# STM32WBA52xx register map
File version: 1.0
Registers are 32-bit, read-write, reset 0x0 unless marked. A register's access mark holds for its fields unless they carry their own. Offsets are from the block's base; lines under a group give offsets from that group; [hi:lo] are bit positions; {n}, {i} and the like mark numbered series; 'fields as' and 'values as' point back to an identical list; <NAME> marks a mode.

## Memory map
0x0BF8FE40 RSSLIB_PFUNC — RSSLib function pointer structure
0x40000000 TIM2 — TIM
0x40000400 TIM3 — TIM
0x40002C00 WWDG
0x40003000 IWDG
0x40004400 USART2 — Universal Synchronous Asynchronous Receiver Transmitter
0x40005400 I2C1 — Inter-integrated Circuit Interface
0x40009400 LPTIM2 — LPTIMER
0x40012C00 TIM1 — TIM
0x40013000 SPI1 — SPI
0x40013800 USART1 — Universal Synchronous Asynchronous Receiver Transmitter
0x40014400 TIM16 — TIM
0x40014800 TIM17 — TIM
0x40020000 GPDMA1 — DMA Controller
0x40022000 FLASH — FLASH Registers
0x40023000 CRC — CRC calculation unit
0x40024000 TSC
0x40026000 RAMCFG
0x40030400 ICACHE — Instruction Cache
0x40032400 GTZC_TZSC — Global TrustZone Controller
0x40032C00 GTZC_MPCBB1
0x40033000 GTZC_MPCBB2
0x40034000 GTZC_MPCBB6
0x42020000 GPIOA — General Purpose I/O
0x42020400 GPIOB — General Purpose I/O
0x42020800 GPIOC — General Purpose I/O
0x42021C00 GPIOH — General Purpose I/O
0x420C0000 AES — AES hardware accelerator
0x420C0400 HASH
0x420C0800 RNG
0x420C0C00 SAES — AES hardware accelerator
0x420C1C00 HSEM — HW Semaphore HSEM
0x420C2000 PKA
0x46000400 SYSCFG — System configuration controller
0x46002000 SPI3 — SPI
0x46002400 LPUART1 — Universal Synchronous Asynchronous Receiver Transmitter
0x46002800 I2C3 — Inter-integrated Circuit Interface
0x46004400 LPTIM1 — LPTIMER
0x46007800 RTC — Real-Time Clock
0x46007C00 TAMP — Tamper and backup registers
0x46020800 PWR — Power Control
0x46020C00 RCC — Reset and Clock Control
0x46021000 ADC4 — Analog to Digital Converter (ADC)
0x46022000 EXTI — Asynch Interrupt/Event Controller (EXTI)
0xE0044000 DBGMCU — Debug MCU

## Interrupts
0 WWDG — Window WatchDog interrupt
2 RTC — RTC non-secure interrupt
3 RTC_S (RTC) — RTC secure interrupt
4 TAMP — Tamper global interrupt
5 RAMCFG — RAMCFG global interrupt
6 FLASH — FLASH non-secure global interrupt
7 FLASH_S (FLASH) — FLASH secure global interrupt
9 RCC — RCC non secure global interrupt
10 RCC_S (RCC) — RCC secure global interrupt
{n+11} EXTI{n} (EXTI) (n=0..15) — EXTI Line{n} interrupt
27 IWDG — IWDG global interrupt
28 SAES — Secure AES global interrupt
{n+29} GPDMA1_Channel{n} (GPDMA1) (n=0..7) — GPDMA1 Channel {n} global interrupt
37 TIM1_BRK (TIM1) — TIM1 Break interrupt
38 TIM1_UP (TIM1) — TIM1 Update interrupt
39 TIM1_TRG_COM (TIM1) — TIM1 Trigger and Commutation interrupt
40 TIM1_CC (TIM1) — TIM1 Capture Compare interrupt
41 TIM2 — TIM2 global interrupt
42 TIM3 — TIM3 global interrupt
43 I2C1_EV (I2C1) — I2C1 Event interrupt
44 I2C1_ER (I2C1) — I2C1 Error interrupt
45 SPI1 — SPI1 global interrupt
46 USART1 — USART1 global interrupt
47 USART2 — USART2 global interrupt
48 LPUART1 — LPUART1 global interrupt
49 LPTIM1 — LPTIM1 global interrupt
50 LPTIM2 — LPTIM2 global interrupt
51 TIM16 — TIM16 global interrupt
52 TIM17 — TIM17 global interrupt
54 I2C3_EV (I2C3) — I2C3 Event interrupt
55 I2C3_ER (I2C3) — I2C3 Error interrupt
57 TSC — Touch Sense Controller global interrupt
58 AES — AES global interrupt
59 RNG — RNG global interrupt
61 HASH — HASH global interrupt
62 PKA — PKA global interrupt
63 SPI3 — SPI3 global interrupt
64 ICACHE — Instruction cache global interrupt
65 ADC4 — ADC4 global interrupt
68 HSEM — HSEM non-secure global interrupt
69 HSEM_S (HSEM) — HSEM secure global interrupt

## RSSLIB_PFUNC — RSSLib function pointer structure
Base 0x0BF8FE40
0x28 CloseExitHDP ro — RSSLIB Close and exit HDP

## WWDG
Base 0x40002C00
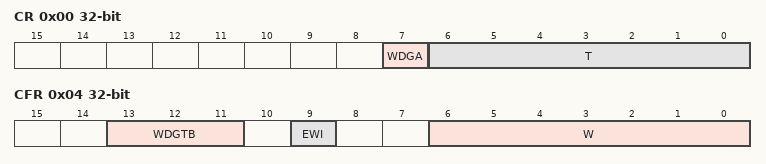
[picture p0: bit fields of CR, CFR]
0x00 CR — WWDG Control register
  [7] WDGA — Activation bit
  [6:0] T — T[6:0] bits (7-Bit counter (MSB to LSB))
0x04 CFR — WWDG Configuration register
  [13:11] WDGTB — WDGTB[2:0] bits (Timer Base)
    0=PRESCALER_1 (WWDG counter clock = (PCLK1/4096)/1); 1=PRESCALER_2 (WWDG counter clock = (PCLK1/4096)/2); 2=PRESCALER_4 (WWDG counter clock = (PCLK1/4096)/4); 3=PRESCALER_8 (WWDG counter clock = (PCLK1/4096)/8); 4=PRESCALER_16 (WWDG counter clock = (PCLK1/4096)/16); 5=PRESCALER_32 (WWDG counter clock = (PCLK1/4096)/32); 6=PRESCALER_64 (WWDG counter clock = (PCLK1/4096)/64); 7=PRESCALER_128 (WWDG counter clock = (PCLK1/4096)/128)
  [9] EWI — Early Wakeup Interrupt
  [6:0] W — W[6:0] bits (7-bit window value)
0x08 SR — WWDG Status register
  [0] EWIF — Early Wakeup Interrupt Flag
